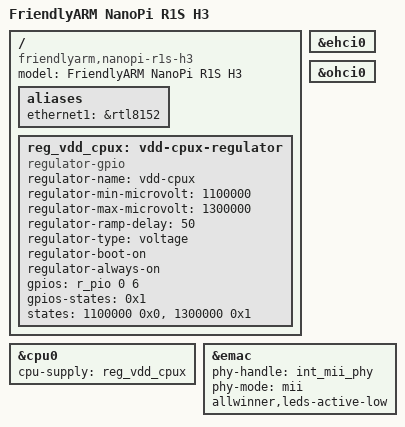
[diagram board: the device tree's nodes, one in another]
/dts-v1/;

#include "sun8i-h3-nanopi.dtsi"

/ {
	model = "FriendlyARM NanoPi R1S H3";
	compatible = "friendlyarm,nanopi-r1s-h3", "allwinner,sun8i-h3";

	aliases {
		ethernet1 = &rtl8152;
	};

	reg_vdd_cpux: vdd-cpux-regulator {
		compatible = "regulator-gpio";
		regulator-name = "vdd-cpux";
		regulator-min-microvolt = <1100000>;
		regulator-max-microvolt = <1300000>;
		regulator-ramp-delay = <50>;
		regulator-type = "voltage";
		regulator-boot-on;
		regulator-always-on;
		gpios = <&r_pio 0 6 GPIO_ACTIVE_HIGH>; /* PL6 */
		gpios-states = <0x1>;
		states = <1100000 0x0>, <1300000 0x1>;
	};
};

&cpu0 {
	cpu-supply = <&reg_vdd_cpux>;
};

&ehci0 {
	status = "okay";
};

&ohci0 {
	status = "okay";
};

&emac {
	phy-handle = <&int_mii_phy>;
	phy-mode = "mii";
	allwinner,leds-active-low;
	status = "okay";
};
